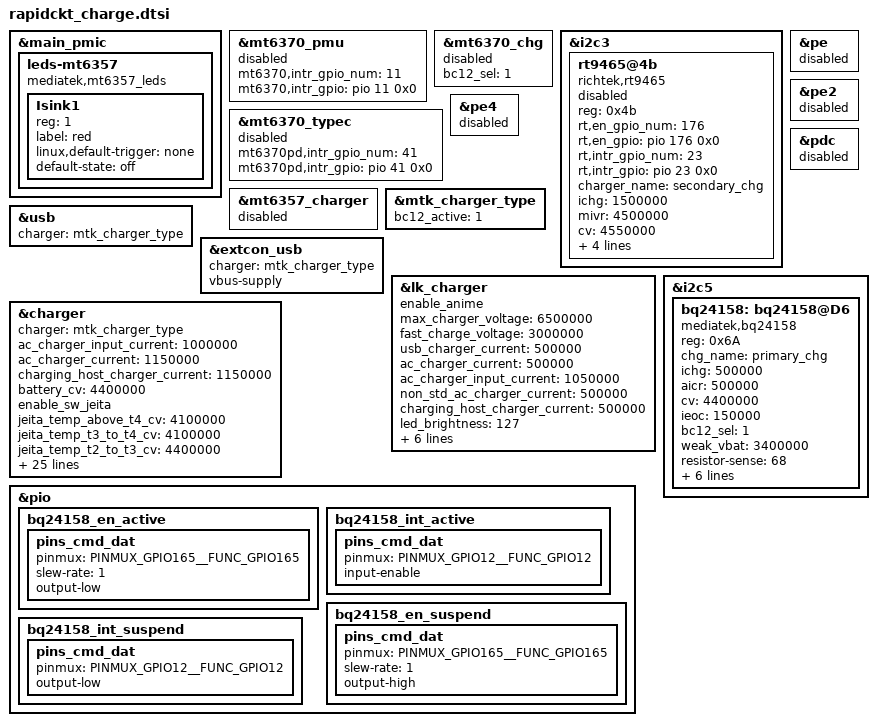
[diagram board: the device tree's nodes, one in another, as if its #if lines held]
// SPDX-License-Identifier: GPL-2.0+

&main_pmic {
	leds-mt6357 {
		compatible = "mediatek,mt6357_leds";
		Isink1 {
			reg = <1>;
			label = "red";
			linux,default-trigger = "none";
			default-state = "off";
		};
	};
};

&mt6370_pmu {
	mt6370,intr_gpio_num = <11>; /* direct defined GPIO num */
	mt6370,intr_gpio = <&pio 11 0x0>;
	status = "disabled";
};

&mt6370_chg {
	bc12_sel = <1>;
	status = "disabled";
};

&i2c3 {
	rt9465@4b {
		compatible = "richtek,rt9465";
		reg = <0x4b>;
		status = "disabled";
		rt,en_gpio_num = <176>;
		rt,en_gpio = <&pio 176 0x0>;
		rt,intr_gpio_num = <23>; /* direct defined GPIO num */
		rt,intr_gpio = <&pio 23 0x0>;
		interrupt-names = "wdtmri";
		charger_name = "secondary_chg";
		ichg = <1500000>; /* uA */
		mivr = <4500000>; /* uV */
		cv = <4550000>; /* uV */
		ieoc = <700000>; /* uA */
		safety_timer = <12>; /* hour */
		en_st; /* safety timer */
		/* en_te; */
		en_wdt;
	};
};

&mt6370_typec {
	mt6370pd,intr_gpio_num = <41>; /* direct defined GPIO num */
	mt6370pd,intr_gpio = <&pio 41 0x0>;
	status = "disabled";
};

&mt6357_charger {
	status = "disabled";
};

&pe {
	status = "disabled";
};

&pe2 {
	status = "disabled";
};

&pe4 {
	status = "disabled";
};

&pdc {
	status = "disabled";
};

&mtk_charger_type {
	bc12_active = <1>;
};

&usb {
	charger = <&mtk_charger_type>;
};

&extcon_usb {
	charger = <&mtk_charger_type>;
	vbus-supply;
};

&lk_charger {
	enable_anime;
	max_charger_voltage = <6500000>;
	fast_charge_voltage = <3000000>;

	/* charging current */
	usb_charger_current = <500000>;
	ac_charger_current = <500000>;
	ac_charger_input_current = <1050000>;
	non_std_ac_charger_current = <500000>;
	charging_host_charger_current = <500000>;

	led_brightness = <127>;
	blinking_times = <6>;
	blinking_period = <1500>;
	temp_t4_threshold = <55>;
	temp_t3_threshold = <45>;
	temp_t1_threshold = <6>;
	temp_t0_threshold = <1>;
};

&charger {
	charger = <&mtk_charger_type>;
	/delete-property/enable_pe_plus;
	/delete-property/enable_pe_2;
	/delete-property/enable_pe_3;
	/delete-property/enable_pe_4;
	/delete-property/enable_type_c;
	/delete-property/power_path_support;
	/delete-property/enable_min_charge_temp;
	/delete-property/enable_dynamic_mivr;
	ac_charger_input_current = <1000000>;
	ac_charger_current = <1150000>;
	charging_host_charger_current = <1150000>;
	battery_cv = <4400000>;
	enable_sw_jeita;
	/* sw jeita */
	jeita_temp_above_t4_cv = <4100000>;
	jeita_temp_t3_to_t4_cv = <4100000>;
	jeita_temp_t2_to_t3_cv = <4400000>;
	jeita_temp_t1_to_t2_cv = <4400000>;
	jeita_temp_t0_to_t1_cv = <4400000>;
	jeita_temp_below_t0_cv = <4400000>;
	jeita_temp_above_t4_current = <0>;
	jeita_temp_t3_to_t4_current = <1150000>;
	jeita_temp_t2_to_t3_current = <1150000>;
	jeita_temp_t1_to_t2_current = <550000>;
	jeita_temp_t0_to_t1_current = <550000>;
	jeita_temp_below_t0_current = <0>;

#if defined(TARGET_BUILD_IEEE1725)
	temp_t4_thres = <53>;
#else
	temp_t4_thres = <55>;
#endif
	temp_t4_thres_minus_x_degree = <51>;
	temp_t3_thres = <42>;
	temp_t3_thres_minus_x_degree = <43>;
	temp_t2_thres = <11>;
	temp_t2_thres_plus_x_degree = <10>;
	temp_t1_thres = <6>;
	temp_t1_thres_plus_x_degree = <5>;
#if defined(TARGET_BUILD_IEEE1725)
	temp_t0_thres = <2>;
	temp_t0_thres_plus_x_degree = <1>;
	temp_neg_10_thres = <2>;
#else
	temp_t0_thres = <1>;
	temp_t0_thres_plus_x_degree = <0>;
	temp_neg_10_thres = <1>;
#endif

	enable_min_charge_temp;
	min_charge_temp = <1>;
#if defined(TARGET_BUILD_IEEE1725)
	min_charge_temp_plus_x_degree = <2>;
	max_charge_temp = <53>;
#else
	min_charge_temp_plus_x_degree = <1>;
	max_charge_temp = <55>;
#endif
	max_charge_temp_minus_x_degree = <51>;
};

&pio {
	bq24158_en_active:bq24158_en_active {
		pins_cmd_dat {
			pinmux = <PINMUX_GPIO165__FUNC_GPIO165>;
			slew-rate = <1>;
			output-low;
		};
	};
	bq24158_int_active: bq24158_int_active {
		pins_cmd_dat {
			pinmux = <PINMUX_GPIO12__FUNC_GPIO12>;
			input-enable;
		};
	};
	bq24158_en_suspend:bq24158_en_suspend {
		pins_cmd_dat {
			pinmux = <PINMUX_GPIO165__FUNC_GPIO165>;
			slew-rate = <1>;
			output-high;
		};
	};
	bq24158_int_suspend: bq24158_int_suspend {
		pins_cmd_dat {
			pinmux = <PINMUX_GPIO12__FUNC_GPIO12>;
			output-low;
		};
	};
};

&i2c5 {
	bq24158:bq24158@D6{
		compatible = "mediatek,bq24158";
		reg = <0x6A>;
		chg_name = "primary_chg";
		ichg = <500000>;		/* uA */
		aicr = <500000>;		/* uA */
		cv = <4400000>;			/* uA */
		ieoc = <150000>;		/* uA */
		bc12_sel = <1>;
		weak_vbat = <3400000>;
		resistor-sense = <68>;
		interrupt-parent = <&pio>;
		interrupts = <12 IRQ_TYPE_LEVEL_LOW>;
		interrupt-names = "bq24158_chg_stat_irq";
		pinctrl-names = "bq24158_active", "bq24158_suspend";
		pinctrl-0 = <&bq24158_en_active &bq24158_int_active>;
		pinctrl-1 = <&bq24158_en_suspend &bq24158_int_suspend>;
		status = "okay";
	};
};
